# R7FA4W1AD register map
Vendor: Renesas; Series: RA4; File version: 1.0
CPU: CM4 r0p1, little endian, MPU, FPU, VTOR, 4 interrupt priority bits
Registers are 8-bit, read-write, reset 0x0 unless marked. A register's access mark holds for its fields unless they carry their own. Offsets are from the block's base; [hi:lo] are bit positions; {n}, {i} and the like mark numbered series.

## DAC8 — 8-bit D/A converter
Base 0x4009E000
{0x0+i} DACS{i} (i=0..1) — D/A Conversion Value Setting Register {i}
  [7:0] DACS — DACS D/A conversion store data note: When 8-bit D/A Converter output is selected as the reference input for the ACMPLP in the COMPSEL1 register, and ACMPLP operation is enabled (COMPMDR.CnENB = 1), changing the DACS[7:0] bits for the channel in use isprohibited.
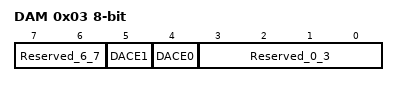
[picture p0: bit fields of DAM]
0x03 DAM — D/A Converter Mode Register
  [7:6] Reserved_6_7 — These bits are read as 00. The write value should be 00.
  [5] DACE1 — D/A Operation Enable 1
  [4] DACE0 — D/A Operation Enable 0
  [3:0] Reserved_0_3 — These bits are read as 0000. The write value should be 0000.

## DAC12 — 12-bit D/A converter
Base 0x4005E000
0x00 DADR0 16-bit — D/A Data Register 0
  [15:0] DADR — D/A Data RegisterNOTE: When DADPR.DPSEL = 0, the high,order 4 bits are fixed to 0: right justified format. When DADPR.DPSEL = 1, the low,order 4 bits are fixed to 0: left justified format.
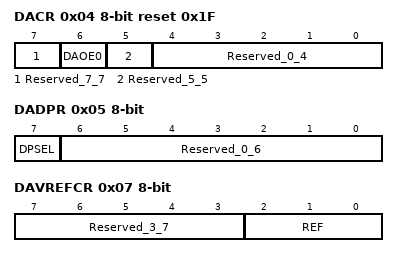
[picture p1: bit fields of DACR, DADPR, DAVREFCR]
0x04 DACR reset 0x1F — D/A Control Register
  [7] Reserved_7_7 — This bit is read as 0. The write value should be 0.
  [6] DAOE0 — D/A Output Enable 0
  [5] Reserved_5_5 — This bit is read as 0. The write value should be 0.
  [4:0] Reserved_0_4 — These bits are read as 11111. The write value should be 11111.
0x05 DADPR — DADR0 Format Select Register
  [7] DPSEL — DADRm Format Select
  [6:0] Reserved_0_6 — These bits are read as 0000000. The write value should be 0000000.
0x06 DAADSCR — D/A,A/D Synchronous Start Control Register
  [7] DAADST — D/A,A/D Synchronous Conversion
0x07 DAVREFCR — D/A VREF Control Register
  [7:3] Reserved_3_7 — These bits are read as 00000. The write value should be 00000.
  [2:0] REF — D/A Reference Voltage Select

## ACMPLP — Low,Power Analog Comparator
Base 0x40085E00
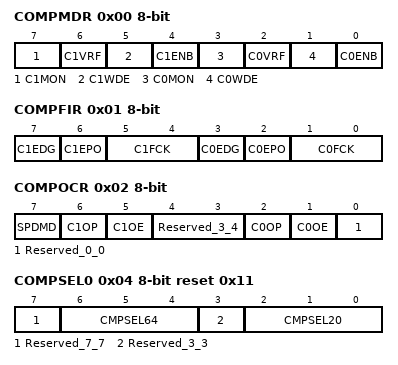
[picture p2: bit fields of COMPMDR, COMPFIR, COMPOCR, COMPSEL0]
0x00 COMPMDR — ACMPLP Mode Setting Register
  [7] C1MON ro — ACMPLP1 Monitor Flag
  [6] C1VRF — ACMPLP1 Reference Voltage Selection
  [5] C1WDE — ACMPLP1 Window Function Mode Enable
  [4] C1ENB — ACMPLP1 Operation Enable
  [3] C0MON ro — ACMPLP0 Monitor Flag
  [2] C0VRF — ACMPLP0 Reference Voltage Selection
  [1] C0WDE — ACMPLP0 Window Function Mode Enable
  [0] C0ENB — ACMPLP0 Operation Enable
0x01 COMPFIR — ACMPLP Filter Control Register
  [7] C1EDG — ACMPLP1 Edge Detection Selection
  [6] C1EPO — ACMPLP1 Edge Polarity Switching
  [5:4] C1FCK — ACMPLP1 Filter Select
  [3] C0EDG — ACMPLP0 Edge Detection Selection
  [2] C0EPO — ACMPLP0 Edge Polarity Switching
  [1:0] C0FCK — ACMPLP0 Filter Select
0x02 COMPOCR — ACMPLP Output Control Register
  [7] SPDMD — ACMPLP0/ACMPLP1 Speed Selection
  [6] C1OP — ACMPLP1 VCOUT Output Polarity Selection
  [5] C1OE — ACMPLP1 VCOUT Pin Output Enable
  [4:3] Reserved_3_4 — These bits are read as 00. The write value should be 00.
  [2] C0OP — ACMPLP0 VCOUT Output Polarity Selection
  [1] C0OE — ACMPLP0 VCOUT Pin Output Enable
  [0] Reserved_0_0 — This bit is read as 0. The write value should be 0.
0x04 COMPSEL0 reset 0x11 — Comparator Input Select Register
  [7] Reserved_7_7 — This bit is read as 0. The write value should be 0.
  [6:4] CMPSEL64 — ACMPLP1 Input (IVCMP1) Selection
  [3] Reserved_3_3 — This bit is read as 0. The write value should be 0.
  [2:0] CMPSEL20 — ACMPLP0 Input(IVCMP0) Selection
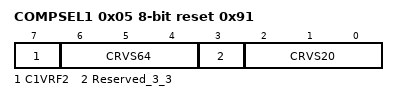
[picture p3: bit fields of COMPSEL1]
0x05 COMPSEL1 reset 0x91 — Comparator Reference Voltage Select Register
  [7] C1VRF2 — ACMPLP1 Reference Voltage Selection
  [6:4] CRVS64 — ACMPLP1 Reference Voltage(IVREF1) Selection
  [3] Reserved_3_3 — This bit is read as 0. The write value should be 0.
  [2:0] CRVS20 — ACMPLP0 Reference Voltage(IVREF0) Selection*

## TSN — Temperature Sensor
Base 0x407EC000
0x228 TSCDRH ro reset not defined — Temperature Sensor Calibration Data Register H
  [7:0] TSCDRH — The calibration data stores the higher 8 bits of the convertedvalue.
0x229 TSCDRL ro reset not defined — Temperature Sensor Calibration Data Register L
  [7:0] TSCDRL — The calibration data stores the lower 8 bits of the convertedvalue.
